# WKUP_CTRL_MMR0_CFG0 register map
Vendor: Texas Instruments
Registers are 32-bit, read-write, reset 0x0 unless marked. A register's access mark holds for its fields unless they carry their own. Offsets are as the file gives them; [hi:lo] are bit positions; {n}, {i} and the like mark numbered series.

## WKUP_CTRL_MMR0_CFG0 (part 11 of 11)
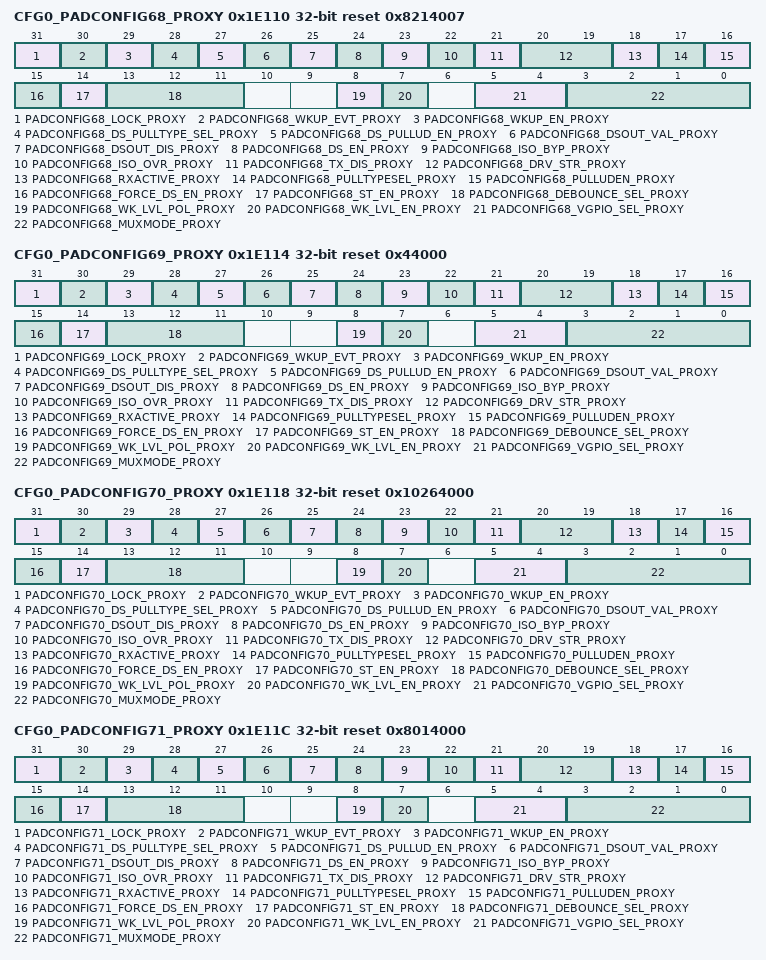
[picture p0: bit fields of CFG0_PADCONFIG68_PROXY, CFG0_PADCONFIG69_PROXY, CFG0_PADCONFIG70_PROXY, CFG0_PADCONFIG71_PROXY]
0x1E110 CFG0_PADCONFIG68_PROXY access per field reset 0x8214007
  [31] PADCONFIG68_LOCK_PROXY rw — Lock 0 - Padconfig register is unlocked 1 - Padconfig register is locked from further writes
  [30] PADCONFIG68_WKUP_EVT_PROXY ro — Wakeup event status 0 - No wake event on pin 1 - Wake event occurred on pin
  [29] PADCONFIG68_WKUP_EN_PROXY rw — Wakeup enable 0 - Wakeup operation disabled 1 - Wakeup operation enabled
  [28] PADCONFIG68_DS_PULLTYPE_SEL_PROXY rw — Deep Sleep pull-up/down selection 0 - Offmode pulldown selected 1 - Offmode pullup selected
  [27] PADCONFIG68_DS_PULLUD_EN_PROXY rw — Deep Sleep pull-up/down enable (active low) 0 - Pullup / pulldown is enabled 1 - Pullup / pulldown is disabled
  [26] PADCONFIG68_DSOUT_VAL_PROXY rw — Deep Sleep output value 0 - Output value is 0 1 - Output value is 1
  [25] PADCONFIG68_DSOUT_DIS_PROXY rw — Deep Sleep output enable 0 - Output enabled 1 - Output disabled
  [24] PADCONFIG68_DS_EN_PROXY rw — Deep Sleep override control 0 - IO keeps its previous state when Deep Sleep is active 1 - IO state is forced to OFF mode value when Deep Sleep is active
  [23] PADCONFIG68_ISO_BYP_PROXY rw — Isolation Bypass 0 - IO isolation is preserved 1 - IO isolation is bypassed
  [22] PADCONFIG68_ISO_OVR_PROXY rw — Isolation Override 0 - IO isolation is preserved 1 - IO isolation is overridden
  [21] PADCONFIG68_TX_DIS_PROXY rw — Driver Disable 0 - Driver is enabled 1 - Driver is disabled
  [20:19] PADCONFIG68_DRV_STR_PROXY rw — Drive Strength Control . Selects the drive strength value for LVCMOS pins. (Does not apply to other pin types)
  [18] PADCONFIG68_RXACTIVE_PROXY rw — Input enable for the Pad 0 - Receiver disabled 1 - Receiver enabled
  [17] PADCONFIG68_PULLTYPESEL_PROXY rw — Pad Pullup / Pulldown type selection 0 - Pulldown selected 1 - Pullup selected
  [16] PADCONFIG68_PULLUDEN_PROXY rw — Pad Pullup / Pulldown enable. This is an active low signal. 0 - Pullup / Pulldown enabled 1 - Pullup / Pulldown disabled
  [15] PADCONFIG68_FORCE_DS_EN_PROXY rw — Enable pad Deep Sleep controls by overriding SMS gating 0 - Deep Sleep pad controls are gated by the SMS 1 - Activate Deep Sleep pad controls (override SMS gating logic)
  [14] PADCONFIG68_ST_EN_PROXY rw — Receiver Schmitt Trigger enable 0 - Schmitt trigger input disabled 1 - Schmitt trigger input enabled
  [13:11] PADCONFIG68_DEBOUNCE_SEL_PROXY rw — Selects the debounce period for the pad.
  [8] PADCONFIG68_WK_LVL_POL_PROXY rw — Level Sensitive Wakeup Polarity This bit is not relevant unless wk_lvl_en is set to 1'b1. 0 - Low. A low (0) value on the pin causes a wakeup 1 - High. A high (1) value on the pin causes a wakeup
  [7] PADCONFIG68_WK_LVL_EN_PROXY rw — Level Sensitive Wakeup Enable 0 - Disabled. Wakeup is triggered by change of the pin input value 1 - Enabled. Wakeup is triggered when the pin matches the value specified by wk_lvl_pol. The chosen polarity must be maintained. (e.g. until wakeup completion is confirmed)
  [5:4] PADCONFIG68_VGPIO_SEL_PROXY rw — Virtual WKUP_GPIO instance select. These bits select which instance of GPIO is used for this I/O pad. This allows protection between two different Processor virtual worlds. These bits have no effect if GPIO mode (muxmode=7) is not selected for the PAD. Field values (others are reserved): 2'b00 - Implement GPIO in GPIO_WKUP_0 instance 2'b01 - Implement GPIO in GPIO_WKUP_1 instance
  [3:0] PADCONFIG68_MUXMODE_PROXY rw — Pad functional signal mux selection Field values (others are reserved): 0000b - Mux Mode 0 0001b - Mux Mode 1 0010b - Mux Mode 2 0011b - Mux Mode 3 0100b - Mux Mode 4 0101b - Mux Mode 5 0110b - Mux Mode 6 0111b - Mux Mode 7 1111b - Mux Mode 15
0x1E114 CFG0_PADCONFIG69_PROXY access per field reset 0x44000
  [31] PADCONFIG69_LOCK_PROXY rw — Lock 0 - Padconfig register is unlocked 1 - Padconfig register is locked from further writes
  [30] PADCONFIG69_WKUP_EVT_PROXY ro — Wakeup event status 0 - No wake event on pin 1 - Wake event occurred on pin
  [29] PADCONFIG69_WKUP_EN_PROXY rw — Wakeup enable 0 - Wakeup operation disabled 1 - Wakeup operation enabled
  [28] PADCONFIG69_DS_PULLTYPE_SEL_PROXY rw — Deep Sleep pull-up/down selection 0 - Offmode pulldown selected 1 - Offmode pullup selected
  [27] PADCONFIG69_DS_PULLUD_EN_PROXY rw — Deep Sleep pull-up/down enable (active low) 0 - Pullup / pulldown is enabled 1 - Pullup / pulldown is disabled
  [26] PADCONFIG69_DSOUT_VAL_PROXY rw — Deep Sleep output value 0 - Output value is 0 1 - Output value is 1
  [25] PADCONFIG69_DSOUT_DIS_PROXY rw — Deep Sleep output enable 0 - Output enabled 1 - Output disabled
  [24] PADCONFIG69_DS_EN_PROXY rw — Deep Sleep override control 0 - IO keeps its previous state when Deep Sleep is active 1 - IO state is forced to OFF mode value when Deep Sleep is active
  [23] PADCONFIG69_ISO_BYP_PROXY rw — Isolation Bypass 0 - IO isolation is preserved 1 - IO isolation is bypassed
  [22] PADCONFIG69_ISO_OVR_PROXY rw — Isolation Override 0 - IO isolation is preserved 1 - IO isolation is overridden
  [21] PADCONFIG69_TX_DIS_PROXY rw — Driver Disable 0 - Driver is enabled 1 - Driver is disabled
  [20:19] PADCONFIG69_DRV_STR_PROXY rw — Drive Strength Control . Selects the drive strength value for LVCMOS pins. (Does not apply to other pin types)
  [18] PADCONFIG69_RXACTIVE_PROXY rw — Input enable for the Pad 0 - Receiver disabled 1 - Receiver enabled
  [17] PADCONFIG69_PULLTYPESEL_PROXY rw — Pad Pullup / Pulldown type selection 0 - Pulldown selected 1 - Pullup selected
  [16] PADCONFIG69_PULLUDEN_PROXY rw — Pad Pullup / Pulldown enable. This is an active low signal. 0 - Pullup / Pulldown enabled 1 - Pullup / Pulldown disabled
  [15] PADCONFIG69_FORCE_DS_EN_PROXY rw — Enable pad Deep Sleep controls by overriding SMS gating 0 - Deep Sleep pad controls are gated by the SMS 1 - Activate Deep Sleep pad controls (override SMS gating logic)
  [14] PADCONFIG69_ST_EN_PROXY rw — Receiver Schmitt Trigger enable 0 - Schmitt trigger input disabled 1 - Schmitt trigger input enabled
  [13:11] PADCONFIG69_DEBOUNCE_SEL_PROXY rw — Selects the debounce period for the pad.
  [8] PADCONFIG69_WK_LVL_POL_PROXY rw — Level Sensitive Wakeup Polarity This bit is not relevant unless wk_lvl_en is set to 1'b1. 0 - Low. A low (0) value on the pin causes a wakeup 1 - High. A high (1) value on the pin causes a wakeup
  [7] PADCONFIG69_WK_LVL_EN_PROXY rw — Level Sensitive Wakeup Enable 0 - Disabled. Wakeup is triggered by change of the pin input value 1 - Enabled. Wakeup is triggered when the pin matches the value specified by wk_lvl_pol. The chosen polarity must be maintained. (e.g. until wakeup completion is confirmed)
  [5:4] PADCONFIG69_VGPIO_SEL_PROXY rw — Virtual WKUP_GPIO instance select. These bits select which instance of GPIO is used for this I/O pad. This allows protection between two different Processor virtual worlds. These bits have no effect if GPIO mode (muxmode=7) is not selected for the PAD. Field values (others are reserved): 2'b00 - Implement GPIO in GPIO_WKUP_0 instance 2'b01 - Implement GPIO in GPIO_WKUP_1 instance
  [3:0] PADCONFIG69_MUXMODE_PROXY rw — Pad functional signal mux selection Field values (others are reserved): 0000b - Mux Mode 0 0001b - Mux Mode 1 0010b - Mux Mode 2 0011b - Mux Mode 3 0100b - Mux Mode 4 0101b - Mux Mode 5 0110b - Mux Mode 6 0111b - Mux Mode 7 1111b - Mux Mode 15
0x1E118 CFG0_PADCONFIG70_PROXY access per field reset 0x10264000
  [31] PADCONFIG70_LOCK_PROXY rw — Lock 0 - Padconfig register is unlocked 1 - Padconfig register is locked from further writes
  [30] PADCONFIG70_WKUP_EVT_PROXY ro — Wakeup event status 0 - No wake event on pin 1 - Wake event occurred on pin
  [29] PADCONFIG70_WKUP_EN_PROXY rw — Wakeup enable 0 - Wakeup operation disabled 1 - Wakeup operation enabled
  [28] PADCONFIG70_DS_PULLTYPE_SEL_PROXY rw — Deep Sleep pull-up/down selection 0 - Offmode pulldown selected 1 - Offmode pullup selected
  [27] PADCONFIG70_DS_PULLUD_EN_PROXY rw — Deep Sleep pull-up/down enable (active low) 0 - Pullup / pulldown is enabled 1 - Pullup / pulldown is disabled
  [26] PADCONFIG70_DSOUT_VAL_PROXY rw — Deep Sleep output value 0 - Output value is 0 1 - Output value is 1
  [25] PADCONFIG70_DSOUT_DIS_PROXY rw — Deep Sleep output enable 0 - Output enabled 1 - Output disabled
  [24] PADCONFIG70_DS_EN_PROXY rw — Deep Sleep override control 0 - IO keeps its previous state when Deep Sleep is active 1 - IO state is forced to OFF mode value when Deep Sleep is active
  [23] PADCONFIG70_ISO_BYP_PROXY rw — Isolation Bypass 0 - IO isolation is preserved 1 - IO isolation is bypassed
  [22] PADCONFIG70_ISO_OVR_PROXY rw — Isolation Override 0 - IO isolation is preserved 1 - IO isolation is overridden
  [21] PADCONFIG70_TX_DIS_PROXY rw — Driver Disable 0 - Driver is enabled 1 - Driver is disabled
  [20:19] PADCONFIG70_DRV_STR_PROXY rw — Drive Strength Control . Selects the drive strength value for LVCMOS pins. (Does not apply to other pin types)
  [18] PADCONFIG70_RXACTIVE_PROXY rw — Input enable for the Pad 0 - Receiver disabled 1 - Receiver enabled
  [17] PADCONFIG70_PULLTYPESEL_PROXY rw — Pad Pullup / Pulldown type selection 0 - Pulldown selected 1 - Pullup selected
  [16] PADCONFIG70_PULLUDEN_PROXY rw — Pad Pullup / Pulldown enable. This is an active low signal. 0 - Pullup / Pulldown enabled 1 - Pullup / Pulldown disabled
  [15] PADCONFIG70_FORCE_DS_EN_PROXY rw — Enable pad Deep Sleep controls by overriding SMS gating 0 - Deep Sleep pad controls are gated by the SMS 1 - Activate Deep Sleep pad controls (override SMS gating logic)
  [14] PADCONFIG70_ST_EN_PROXY rw — Receiver Schmitt Trigger enable 0 - Schmitt trigger input disabled 1 - Schmitt trigger input enabled
  [13:11] PADCONFIG70_DEBOUNCE_SEL_PROXY rw — Selects the debounce period for the pad.
  [8] PADCONFIG70_WK_LVL_POL_PROXY rw — Level Sensitive Wakeup Polarity This bit is not relevant unless wk_lvl_en is set to 1'b1. 0 - Low. A low (0) value on the pin causes a wakeup 1 - High. A high (1) value on the pin causes a wakeup
  [7] PADCONFIG70_WK_LVL_EN_PROXY rw — Level Sensitive Wakeup Enable 0 - Disabled. Wakeup is triggered by change of the pin input value 1 - Enabled. Wakeup is triggered when the pin matches the value specified by wk_lvl_pol. The chosen polarity must be maintained. (e.g. until wakeup completion is confirmed)
  [5:4] PADCONFIG70_VGPIO_SEL_PROXY rw — Virtual WKUP_GPIO instance select. These bits select which instance of GPIO is used for this I/O pad. This allows protection between two different Processor virtual worlds. These bits have no effect if GPIO mode (muxmode=7) is not selected for the PAD. Field values (others are reserved): 2'b00 - Implement GPIO in GPIO_WKUP_0 instance 2'b01 - Implement GPIO in GPIO_WKUP_1 instance
  [3:0] PADCONFIG70_MUXMODE_PROXY rw — Pad functional signal mux selection Field values (others are reserved): 0000b - Mux Mode 0 0001b - Mux Mode 1 0010b - Mux Mode 2 0011b - Mux Mode 3 0100b - Mux Mode 4 0101b - Mux Mode 5 0110b - Mux Mode 6 0111b - Mux Mode 7 1111b - Mux Mode 15
0x1E11C CFG0_PADCONFIG71_PROXY access per field reset 0x8014000
  [31] PADCONFIG71_LOCK_PROXY rw — Lock 0 - Padconfig register is unlocked 1 - Padconfig register is locked from further writes
  [30] PADCONFIG71_WKUP_EVT_PROXY ro — Wakeup event status 0 - No wake event on pin 1 - Wake event occurred on pin
  [29] PADCONFIG71_WKUP_EN_PROXY rw — Wakeup enable 0 - Wakeup operation disabled 1 - Wakeup operation enabled
  [28] PADCONFIG71_DS_PULLTYPE_SEL_PROXY rw — Deep Sleep pull-up/down selection 0 - Offmode pulldown selected 1 - Offmode pullup selected
  [27] PADCONFIG71_DS_PULLUD_EN_PROXY rw — Deep Sleep pull-up/down enable (active low) 0 - Pullup / pulldown is enabled 1 - Pullup / pulldown is disabled
  [26] PADCONFIG71_DSOUT_VAL_PROXY rw — Deep Sleep output value 0 - Output value is 0 1 - Output value is 1
  [25] PADCONFIG71_DSOUT_DIS_PROXY rw — Deep Sleep output enable 0 - Output enabled 1 - Output disabled
  [24] PADCONFIG71_DS_EN_PROXY rw — Deep Sleep override control 0 - IO keeps its previous state when Deep Sleep is active 1 - IO state is forced to OFF mode value when Deep Sleep is active
  [23] PADCONFIG71_ISO_BYP_PROXY rw — Isolation Bypass 0 - IO isolation is preserved 1 - IO isolation is bypassed
  [22] PADCONFIG71_ISO_OVR_PROXY rw — Isolation Override 0 - IO isolation is preserved 1 - IO isolation is overridden
  [21] PADCONFIG71_TX_DIS_PROXY rw — Driver Disable 0 - Driver is enabled 1 - Driver is disabled
  [20:19] PADCONFIG71_DRV_STR_PROXY rw — Drive Strength Control . Selects the drive strength value for LVCMOS pins. (Does not apply to other pin types)
  [18] PADCONFIG71_RXACTIVE_PROXY rw — Input enable for the Pad 0 - Receiver disabled 1 - Receiver enabled
  [17] PADCONFIG71_PULLTYPESEL_PROXY rw — Pad Pullup / Pulldown type selection 0 - Pulldown selected 1 - Pullup selected
  [16] PADCONFIG71_PULLUDEN_PROXY rw — Pad Pullup / Pulldown enable. This is an active low signal. 0 - Pullup / Pulldown enabled 1 - Pullup / Pulldown disabled
  [15] PADCONFIG71_FORCE_DS_EN_PROXY rw — Enable pad Deep Sleep controls by overriding SMS gating 0 - Deep Sleep pad controls are gated by the SMS 1 - Activate Deep Sleep pad controls (override SMS gating logic)
  [14] PADCONFIG71_ST_EN_PROXY rw — Receiver Schmitt Trigger enable 0 - Schmitt trigger input disabled 1 - Schmitt trigger input enabled
  [13:11] PADCONFIG71_DEBOUNCE_SEL_PROXY rw — Selects the debounce period for the pad.
  [8] PADCONFIG71_WK_LVL_POL_PROXY rw — Level Sensitive Wakeup Polarity This bit is not relevant unless wk_lvl_en is set to 1'b1. 0 - Low. A low (0) value on the pin causes a wakeup 1 - High. A high (1) value on the pin causes a wakeup
  [7] PADCONFIG71_WK_LVL_EN_PROXY rw — Level Sensitive Wakeup Enable 0 - Disabled. Wakeup is triggered by change of the pin input value 1 - Enabled. Wakeup is triggered when the pin matches the value specified by wk_lvl_pol. The chosen polarity must be maintained. (e.g. until wakeup completion is confirmed)
  [5:4] PADCONFIG71_VGPIO_SEL_PROXY rw — Virtual WKUP_GPIO instance select. These bits select which instance of GPIO is used for this I/O pad. This allows protection between two different Processor virtual worlds. These bits have no effect if GPIO mode (muxmode=7) is not selected for the PAD. Field values (others are reserved): 2'b00 - Implement GPIO in GPIO_WKUP_0 instance 2'b01 - Implement GPIO in GPIO_WKUP_1 instance
  [3:0] PADCONFIG71_MUXMODE_PROXY rw — Pad functional signal mux selection Field values (others are reserved): 0000b - Mux Mode 0 0001b - Mux Mode 1 0010b - Mux Mode 2 0011b - Mux Mode 3 0100b - Mux Mode 4 0101b - Mux Mode 5 0110b - Mux Mode 6 0111b - Mux Mode 7 1111b - Mux Mode 15
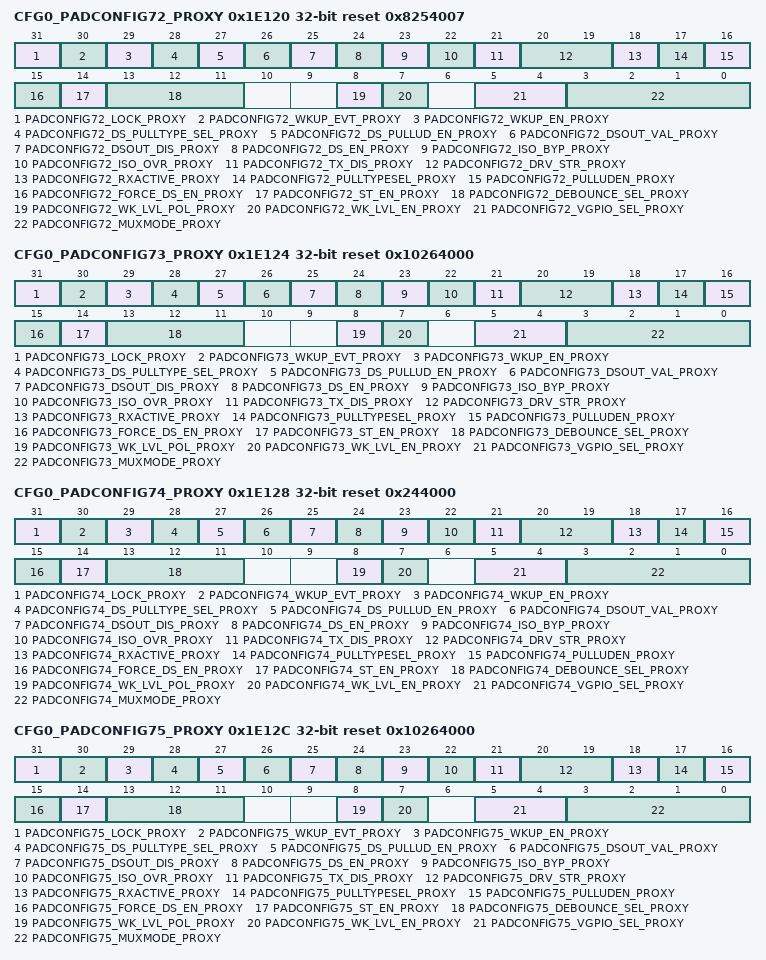
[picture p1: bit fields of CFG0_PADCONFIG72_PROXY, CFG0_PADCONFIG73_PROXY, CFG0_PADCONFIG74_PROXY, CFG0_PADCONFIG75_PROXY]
0x1E120 CFG0_PADCONFIG72_PROXY access per field reset 0x8254007
  [31] PADCONFIG72_LOCK_PROXY rw — Lock 0 - Padconfig register is unlocked 1 - Padconfig register is locked from further writes
  [30] PADCONFIG72_WKUP_EVT_PROXY ro — Wakeup event status 0 - No wake event on pin 1 - Wake event occurred on pin
  [29] PADCONFIG72_WKUP_EN_PROXY rw — Wakeup enable 0 - Wakeup operation disabled 1 - Wakeup operation enabled
  [28] PADCONFIG72_DS_PULLTYPE_SEL_PROXY rw — Deep Sleep pull-up/down selection 0 - Offmode pulldown selected 1 - Offmode pullup selected
  [27] PADCONFIG72_DS_PULLUD_EN_PROXY rw — Deep Sleep pull-up/down enable (active low) 0 - Pullup / pulldown is enabled 1 - Pullup / pulldown is disabled
  [26] PADCONFIG72_DSOUT_VAL_PROXY rw — Deep Sleep output value 0 - Output value is 0 1 - Output value is 1
  [25] PADCONFIG72_DSOUT_DIS_PROXY rw — Deep Sleep output enable 0 - Output enabled 1 - Output disabled
  [24] PADCONFIG72_DS_EN_PROXY rw — Deep Sleep override control 0 - IO keeps its previous state when Deep Sleep is active 1 - IO state is forced to OFF mode value when Deep Sleep is active
  [23] PADCONFIG72_ISO_BYP_PROXY rw — Isolation Bypass 0 - IO isolation is preserved 1 - IO isolation is bypassed
  [22] PADCONFIG72_ISO_OVR_PROXY rw — Isolation Override 0 - IO isolation is preserved 1 - IO isolation is overridden
  [21] PADCONFIG72_TX_DIS_PROXY rw — Driver Disable 0 - Driver is enabled 1 - Driver is disabled
  [20:19] PADCONFIG72_DRV_STR_PROXY rw — Drive Strength Control . Selects the drive strength value for LVCMOS pins. (Does not apply to other pin types)
  [18] PADCONFIG72_RXACTIVE_PROXY rw — Input enable for the Pad 0 - Receiver disabled 1 - Receiver enabled
  [17] PADCONFIG72_PULLTYPESEL_PROXY rw — Pad Pullup / Pulldown type selection 0 - Pulldown selected 1 - Pullup selected
  [16] PADCONFIG72_PULLUDEN_PROXY rw — Pad Pullup / Pulldown enable. This is an active low signal. 0 - Pullup / Pulldown enabled 1 - Pullup / Pulldown disabled
  [15] PADCONFIG72_FORCE_DS_EN_PROXY rw — Enable pad Deep Sleep controls by overriding SMS gating 0 - Deep Sleep pad controls are gated by the SMS 1 - Activate Deep Sleep pad controls (override SMS gating logic)
  [14] PADCONFIG72_ST_EN_PROXY rw — Receiver Schmitt Trigger enable 0 - Schmitt trigger input disabled 1 - Schmitt trigger input enabled
  [13:11] PADCONFIG72_DEBOUNCE_SEL_PROXY rw — Selects the debounce period for the pad.
  [8] PADCONFIG72_WK_LVL_POL_PROXY rw — Level Sensitive Wakeup Polarity This bit is not relevant unless wk_lvl_en is set to 1'b1. 0 - Low. A low (0) value on the pin causes a wakeup 1 - High. A high (1) value on the pin causes a wakeup
  [7] PADCONFIG72_WK_LVL_EN_PROXY rw — Level Sensitive Wakeup Enable 0 - Disabled. Wakeup is triggered by change of the pin input value 1 - Enabled. Wakeup is triggered when the pin matches the value specified by wk_lvl_pol. The chosen polarity must be maintained. (e.g. until wakeup completion is confirmed)
  [5:4] PADCONFIG72_VGPIO_SEL_PROXY rw — Virtual WKUP_GPIO instance select. These bits select which instance of GPIO is used for this I/O pad. This allows protection between two different Processor virtual worlds. These bits have no effect if GPIO mode (muxmode=7) is not selected for the PAD. Field values (others are reserved): 2'b00 - Implement GPIO in GPIO_WKUP_0 instance 2'b01 - Implement GPIO in GPIO_WKUP_1 instance
  [3:0] PADCONFIG72_MUXMODE_PROXY rw — Pad functional signal mux selection Field values (others are reserved): 0000b - Mux Mode 0 0001b - Mux Mode 1 0010b - Mux Mode 2 0011b - Mux Mode 3 0100b - Mux Mode 4 0101b - Mux Mode 5 0110b - Mux Mode 6 0111b - Mux Mode 7 1111b - Mux Mode 15
0x1E124 CFG0_PADCONFIG73_PROXY access per field reset 0x10264000
  [31] PADCONFIG73_LOCK_PROXY rw — Lock 0 - Padconfig register is unlocked 1 - Padconfig register is locked from further writes
  [30] PADCONFIG73_WKUP_EVT_PROXY ro — Wakeup event status 0 - No wake event on pin 1 - Wake event occurred on pin
  [29] PADCONFIG73_WKUP_EN_PROXY rw — Wakeup enable 0 - Wakeup operation disabled 1 - Wakeup operation enabled
  [28] PADCONFIG73_DS_PULLTYPE_SEL_PROXY rw — Deep Sleep pull-up/down selection 0 - Offmode pulldown selected 1 - Offmode pullup selected
  [27] PADCONFIG73_DS_PULLUD_EN_PROXY rw — Deep Sleep pull-up/down enable (active low) 0 - Pullup / pulldown is enabled 1 - Pullup / pulldown is disabled
  [26] PADCONFIG73_DSOUT_VAL_PROXY rw — Deep Sleep output value 0 - Output value is 0 1 - Output value is 1
  [25] PADCONFIG73_DSOUT_DIS_PROXY rw — Deep Sleep output enable 0 - Output enabled 1 - Output disabled
  [24] PADCONFIG73_DS_EN_PROXY rw — Deep Sleep override control 0 - IO keeps its previous state when Deep Sleep is active 1 - IO state is forced to OFF mode value when Deep Sleep is active
  [23] PADCONFIG73_ISO_BYP_PROXY rw — Isolation Bypass 0 - IO isolation is preserved 1 - IO isolation is bypassed
  [22] PADCONFIG73_ISO_OVR_PROXY rw — Isolation Override 0 - IO isolation is preserved 1 - IO isolation is overridden
  [21] PADCONFIG73_TX_DIS_PROXY rw — Driver Disable 0 - Driver is enabled 1 - Driver is disabled
  [20:19] PADCONFIG73_DRV_STR_PROXY rw — Drive Strength Control . Selects the drive strength value for LVCMOS pins. (Does not apply to other pin types)
  [18] PADCONFIG73_RXACTIVE_PROXY rw — Input enable for the Pad 0 - Receiver disabled 1 - Receiver enabled
  [17] PADCONFIG73_PULLTYPESEL_PROXY rw — Pad Pullup / Pulldown type selection 0 - Pulldown selected 1 - Pullup selected
  [16] PADCONFIG73_PULLUDEN_PROXY rw — Pad Pullup / Pulldown enable. This is an active low signal. 0 - Pullup / Pulldown enabled 1 - Pullup / Pulldown disabled
  [15] PADCONFIG73_FORCE_DS_EN_PROXY rw — Enable pad Deep Sleep controls by overriding SMS gating 0 - Deep Sleep pad controls are gated by the SMS 1 - Activate Deep Sleep pad controls (override SMS gating logic)
  [14] PADCONFIG73_ST_EN_PROXY rw — Receiver Schmitt Trigger enable 0 - Schmitt trigger input disabled 1 - Schmitt trigger input enabled
  [13:11] PADCONFIG73_DEBOUNCE_SEL_PROXY rw — Selects the debounce period for the pad.
  [8] PADCONFIG73_WK_LVL_POL_PROXY rw — Level Sensitive Wakeup Polarity This bit is not relevant unless wk_lvl_en is set to 1'b1. 0 - Low. A low (0) value on the pin causes a wakeup 1 - High. A high (1) value on the pin causes a wakeup
  [7] PADCONFIG73_WK_LVL_EN_PROXY rw — Level Sensitive Wakeup Enable 0 - Disabled. Wakeup is triggered by change of the pin input value 1 - Enabled. Wakeup is triggered when the pin matches the value specified by wk_lvl_pol. The chosen polarity must be maintained. (e.g. until wakeup completion is confirmed)
  [5:4] PADCONFIG73_VGPIO_SEL_PROXY rw — Virtual WKUP_GPIO instance select. These bits select which instance of GPIO is used for this I/O pad. This allows protection between two different Processor virtual worlds. These bits have no effect if GPIO mode (muxmode=7) is not selected for the PAD. Field values (others are reserved): 2'b00 - Implement GPIO in GPIO_WKUP_0 instance 2'b01 - Implement GPIO in GPIO_WKUP_1 instance
  [3:0] PADCONFIG73_MUXMODE_PROXY rw — Pad functional signal mux selection Field values (others are reserved): 0000b - Mux Mode 0 0001b - Mux Mode 1 0010b - Mux Mode 2 0011b - Mux Mode 3 0100b - Mux Mode 4 0101b - Mux Mode 5 0110b - Mux Mode 6 0111b - Mux Mode 7 1111b - Mux Mode 15
0x1E128 CFG0_PADCONFIG74_PROXY access per field reset 0x244000
  [31] PADCONFIG74_LOCK_PROXY rw — Lock 0 - Padconfig register is unlocked 1 - Padconfig register is locked from further writes
  [30] PADCONFIG74_WKUP_EVT_PROXY ro — Wakeup event status 0 - No wake event on pin 1 - Wake event occurred on pin
  [29] PADCONFIG74_WKUP_EN_PROXY rw — Wakeup enable 0 - Wakeup operation disabled 1 - Wakeup operation enabled
  [28] PADCONFIG74_DS_PULLTYPE_SEL_PROXY rw — Deep Sleep pull-up/down selection 0 - Offmode pulldown selected 1 - Offmode pullup selected
  [27] PADCONFIG74_DS_PULLUD_EN_PROXY rw — Deep Sleep pull-up/down enable (active low) 0 - Pullup / pulldown is enabled 1 - Pullup / pulldown is disabled
  [26] PADCONFIG74_DSOUT_VAL_PROXY rw — Deep Sleep output value 0 - Output value is 0 1 - Output value is 1
  [25] PADCONFIG74_DSOUT_DIS_PROXY rw — Deep Sleep output enable 0 - Output enabled 1 - Output disabled
  [24] PADCONFIG74_DS_EN_PROXY rw — Deep Sleep override control 0 - IO keeps its previous state when Deep Sleep is active 1 - IO state is forced to OFF mode value when Deep Sleep is active
  [23] PADCONFIG74_ISO_BYP_PROXY rw — Isolation Bypass 0 - IO isolation is preserved 1 - IO isolation is bypassed
  [22] PADCONFIG74_ISO_OVR_PROXY rw — Isolation Override 0 - IO isolation is preserved 1 - IO isolation is overridden
  [21] PADCONFIG74_TX_DIS_PROXY rw — Driver Disable 0 - Driver is enabled 1 - Driver is disabled
  [20:19] PADCONFIG74_DRV_STR_PROXY rw — Drive Strength Control . Selects the drive strength value for LVCMOS pins. (Does not apply to other pin types)
  [18] PADCONFIG74_RXACTIVE_PROXY rw — Input enable for the Pad 0 - Receiver disabled 1 - Receiver enabled
  [17] PADCONFIG74_PULLTYPESEL_PROXY rw — Pad Pullup / Pulldown type selection 0 - Pulldown selected 1 - Pullup selected
  [16] PADCONFIG74_PULLUDEN_PROXY rw — Pad Pullup / Pulldown enable. This is an active low signal. 0 - Pullup / Pulldown enabled 1 - Pullup / Pulldown disabled
  [15] PADCONFIG74_FORCE_DS_EN_PROXY rw — Enable pad Deep Sleep controls by overriding SMS gating 0 - Deep Sleep pad controls are gated by the SMS 1 - Activate Deep Sleep pad controls (override SMS gating logic)
  [14] PADCONFIG74_ST_EN_PROXY rw — Receiver Schmitt Trigger enable 0 - Schmitt trigger input disabled 1 - Schmitt trigger input enabled
  [13:11] PADCONFIG74_DEBOUNCE_SEL_PROXY rw — Selects the debounce period for the pad.
  [8] PADCONFIG74_WK_LVL_POL_PROXY rw — Level Sensitive Wakeup Polarity This bit is not relevant unless wk_lvl_en is set to 1'b1. 0 - Low. A low (0) value on the pin causes a wakeup 1 - High. A high (1) value on the pin causes a wakeup
  [7] PADCONFIG74_WK_LVL_EN_PROXY rw — Level Sensitive Wakeup Enable 0 - Disabled. Wakeup is triggered by change of the pin input value 1 - Enabled. Wakeup is triggered when the pin matches the value specified by wk_lvl_pol. The chosen polarity must be maintained. (e.g. until wakeup completion is confirmed)
  [5:4] PADCONFIG74_VGPIO_SEL_PROXY rw — Virtual WKUP_GPIO instance select. These bits select which instance of GPIO is used for this I/O pad. This allows protection between two different Processor virtual worlds. These bits have no effect if GPIO mode (muxmode=7) is not selected for the PAD. Field values (others are reserved): 2'b00 - Implement GPIO in GPIO_WKUP_0 instance 2'b01 - Implement GPIO in GPIO_WKUP_1 instance
  [3:0] PADCONFIG74_MUXMODE_PROXY rw — Pad functional signal mux selection Field values (others are reserved): 0000b - Mux Mode 0 0001b - Mux Mode 1 0010b - Mux Mode 2 0011b - Mux Mode 3 0100b - Mux Mode 4 0101b - Mux Mode 5 0110b - Mux Mode 6 0111b - Mux Mode 7 1111b - Mux Mode 15
0x1E12C CFG0_PADCONFIG75_PROXY access per field reset 0x10264000
  [31] PADCONFIG75_LOCK_PROXY rw — Lock 0 - Padconfig register is unlocked 1 - Padconfig register is locked from further writes
  [30] PADCONFIG75_WKUP_EVT_PROXY ro — Wakeup event status 0 - No wake event on pin 1 - Wake event occurred on pin
  [29] PADCONFIG75_WKUP_EN_PROXY rw — Wakeup enable 0 - Wakeup operation disabled 1 - Wakeup operation enabled
  [28] PADCONFIG75_DS_PULLTYPE_SEL_PROXY rw — Deep Sleep pull-up/down selection 0 - Offmode pulldown selected 1 - Offmode pullup selected
  [27] PADCONFIG75_DS_PULLUD_EN_PROXY rw — Deep Sleep pull-up/down enable (active low) 0 - Pullup / pulldown is enabled 1 - Pullup / pulldown is disabled
  [26] PADCONFIG75_DSOUT_VAL_PROXY rw — Deep Sleep output value 0 - Output value is 0 1 - Output value is 1
  [25] PADCONFIG75_DSOUT_DIS_PROXY rw — Deep Sleep output enable 0 - Output enabled 1 - Output disabled
  [24] PADCONFIG75_DS_EN_PROXY rw — Deep Sleep override control 0 - IO keeps its previous state when Deep Sleep is active 1 - IO state is forced to OFF mode value when Deep Sleep is active
  [23] PADCONFIG75_ISO_BYP_PROXY rw — Isolation Bypass 0 - IO isolation is preserved 1 - IO isolation is bypassed
  [22] PADCONFIG75_ISO_OVR_PROXY rw — Isolation Override 0 - IO isolation is preserved 1 - IO isolation is overridden
  [21] PADCONFIG75_TX_DIS_PROXY rw — Driver Disable 0 - Driver is enabled 1 - Driver is disabled
  [20:19] PADCONFIG75_DRV_STR_PROXY rw — Drive Strength Control . Selects the drive strength value for LVCMOS pins. (Does not apply to other pin types)
  [18] PADCONFIG75_RXACTIVE_PROXY rw — Input enable for the Pad 0 - Receiver disabled 1 - Receiver enabled
  [17] PADCONFIG75_PULLTYPESEL_PROXY rw — Pad Pullup / Pulldown type selection 0 - Pulldown selected 1 - Pullup selected
  [16] PADCONFIG75_PULLUDEN_PROXY rw — Pad Pullup / Pulldown enable. This is an active low signal. 0 - Pullup / Pulldown enabled 1 - Pullup / Pulldown disabled
  [15] PADCONFIG75_FORCE_DS_EN_PROXY rw — Enable pad Deep Sleep controls by overriding SMS gating 0 - Deep Sleep pad controls are gated by the SMS 1 - Activate Deep Sleep pad controls (override SMS gating logic)
  [14] PADCONFIG75_ST_EN_PROXY rw — Receiver Schmitt Trigger enable 0 - Schmitt trigger input disabled 1 - Schmitt trigger input enabled
  [13:11] PADCONFIG75_DEBOUNCE_SEL_PROXY rw — Selects the debounce period for the pad.
  [8] PADCONFIG75_WK_LVL_POL_PROXY rw — Level Sensitive Wakeup Polarity This bit is not relevant unless wk_lvl_en is set to 1'b1. 0 - Low. A low (0) value on the pin causes a wakeup 1 - High. A high (1) value on the pin causes a wakeup
  [7] PADCONFIG75_WK_LVL_EN_PROXY rw — Level Sensitive Wakeup Enable 0 - Disabled. Wakeup is triggered by change of the pin input value 1 - Enabled. Wakeup is triggered when the pin matches the value specified by wk_lvl_pol. The chosen polarity must be maintained. (e.g. until wakeup completion is confirmed)
  [5:4] PADCONFIG75_VGPIO_SEL_PROXY rw — Virtual WKUP_GPIO instance select. These bits select which instance of GPIO is used for this I/O pad. This allows protection between two different Processor virtual worlds. These bits have no effect if GPIO mode (muxmode=7) is not selected for the PAD. Field values (others are reserved): 2'b00 - Implement GPIO in GPIO_WKUP_0 instance 2'b01 - Implement GPIO in GPIO_WKUP_1 instance
  [3:0] PADCONFIG75_MUXMODE_PROXY rw — Pad functional signal mux selection Field values (others are reserved): 0000b - Mux Mode 0 0001b - Mux Mode 1 0010b - Mux Mode 2 0011b - Mux Mode 3 0100b - Mux Mode 4 0101b - Mux Mode 5 0110b - Mux Mode 6 0111b - Mux Mode 7 1111b - Mux Mode 15
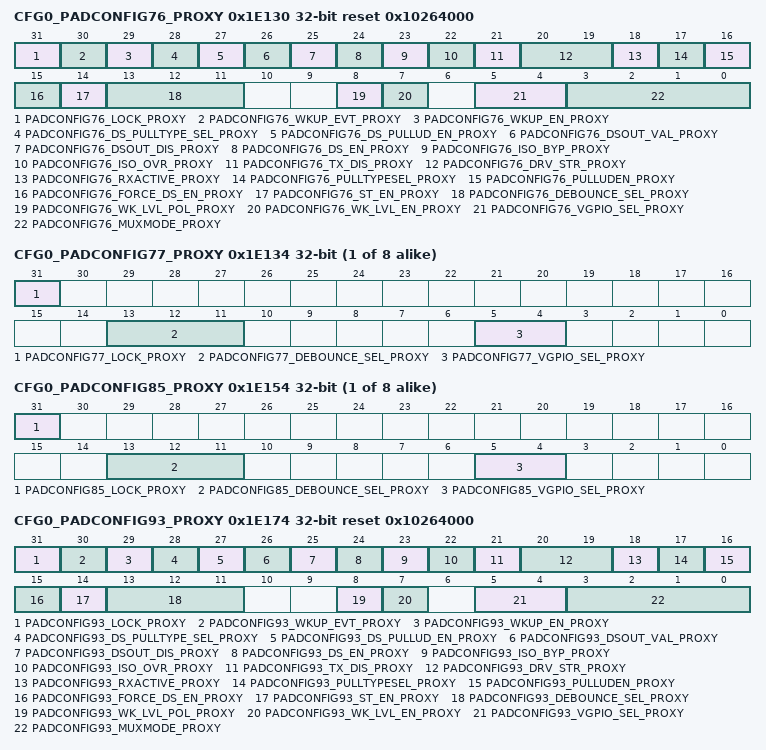
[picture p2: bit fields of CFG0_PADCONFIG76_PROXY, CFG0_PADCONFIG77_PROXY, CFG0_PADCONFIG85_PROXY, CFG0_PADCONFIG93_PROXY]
0x1E130 CFG0_PADCONFIG76_PROXY access per field reset 0x10264000
  [31] PADCONFIG76_LOCK_PROXY rw — Lock 0 - Padconfig register is unlocked 1 - Padconfig register is locked from further writes
  [30] PADCONFIG76_WKUP_EVT_PROXY ro — Wakeup event status 0 - No wake event on pin 1 - Wake event occurred on pin
  [29] PADCONFIG76_WKUP_EN_PROXY rw — Wakeup enable 0 - Wakeup operation disabled 1 - Wakeup operation enabled
  [28] PADCONFIG76_DS_PULLTYPE_SEL_PROXY rw — Deep Sleep pull-up/down selection 0 - Offmode pulldown selected 1 - Offmode pullup selected
  [27] PADCONFIG76_DS_PULLUD_EN_PROXY rw — Deep Sleep pull-up/down enable (active low) 0 - Pullup / pulldown is enabled 1 - Pullup / pulldown is disabled
  [26] PADCONFIG76_DSOUT_VAL_PROXY rw — Deep Sleep output value 0 - Output value is 0 1 - Output value is 1
  [25] PADCONFIG76_DSOUT_DIS_PROXY rw — Deep Sleep output enable 0 - Output enabled 1 - Output disabled
  [24] PADCONFIG76_DS_EN_PROXY rw — Deep Sleep override control 0 - IO keeps its previous state when Deep Sleep is active 1 - IO state is forced to OFF mode value when Deep Sleep is active
  [23] PADCONFIG76_ISO_BYP_PROXY rw — Isolation Bypass 0 - IO isolation is preserved 1 - IO isolation is bypassed
  [22] PADCONFIG76_ISO_OVR_PROXY rw — Isolation Override 0 - IO isolation is preserved 1 - IO isolation is overridden
  [21] PADCONFIG76_TX_DIS_PROXY rw — Driver Disable 0 - Driver is enabled 1 - Driver is disabled
  [20:19] PADCONFIG76_DRV_STR_PROXY rw — Drive Strength Control . Selects the drive strength value for LVCMOS pins. (Does not apply to other pin types)
  [18] PADCONFIG76_RXACTIVE_PROXY rw — Input enable for the Pad 0 - Receiver disabled 1 - Receiver enabled
  [17] PADCONFIG76_PULLTYPESEL_PROXY rw — Pad Pullup / Pulldown type selection 0 - Pulldown selected 1 - Pullup selected
  [16] PADCONFIG76_PULLUDEN_PROXY rw — Pad Pullup / Pulldown enable. This is an active low signal. 0 - Pullup / Pulldown enabled 1 - Pullup / Pulldown disabled
  [15] PADCONFIG76_FORCE_DS_EN_PROXY rw — Enable pad Deep Sleep controls by overriding SMS gating 0 - Deep Sleep pad controls are gated by the SMS 1 - Activate Deep Sleep pad controls (override SMS gating logic)
  [14] PADCONFIG76_ST_EN_PROXY rw — Receiver Schmitt Trigger enable 0 - Schmitt trigger input disabled 1 - Schmitt trigger input enabled
  [13:11] PADCONFIG76_DEBOUNCE_SEL_PROXY rw — Selects the debounce period for the pad.
  [8] PADCONFIG76_WK_LVL_POL_PROXY rw — Level Sensitive Wakeup Polarity This bit is not relevant unless wk_lvl_en is set to 1'b1. 0 - Low. A low (0) value on the pin causes a wakeup 1 - High. A high (1) value on the pin causes a wakeup
  [7] PADCONFIG76_WK_LVL_EN_PROXY rw — Level Sensitive Wakeup Enable 0 - Disabled. Wakeup is triggered by change of the pin input value 1 - Enabled. Wakeup is triggered when the pin matches the value specified by wk_lvl_pol. The chosen polarity must be maintained. (e.g. until wakeup completion is confirmed)
  [5:4] PADCONFIG76_VGPIO_SEL_PROXY rw — Virtual WKUP_GPIO instance select. These bits select which instance of GPIO is used for this I/O pad. This allows protection between two different Processor virtual worlds. These bits have no effect if GPIO mode (muxmode=7) is not selected for the PAD. Field values (others are reserved): 2'b00 - Implement GPIO in GPIO_WKUP_0 instance 2'b01 - Implement GPIO in GPIO_WKUP_1 instance
  [3:0] PADCONFIG76_MUXMODE_PROXY rw — Pad functional signal mux selection Field values (others are reserved): 0000b - Mux Mode 0 0001b - Mux Mode 1 0010b - Mux Mode 2 0011b - Mux Mode 3 0100b - Mux Mode 4 0101b - Mux Mode 5 0110b - Mux Mode 6 0111b - Mux Mode 7 1111b - Mux Mode 15
{0x1E000+4i} CFG0_PADCONFIG{i}_PROXY (i=77..84)
  [31] PADCONFIG{i}_LOCK_PROXY — Lock 0 - Padconfig register is unlocked 1 - Padconfig register is locked from further writes
  [13:11] PADCONFIG{i}_DEBOUNCE_SEL_PROXY — Selects the debounce period for the pad.
  [5:4] PADCONFIG{i}_VGPIO_SEL_PROXY — Virtual WKUP_GPIO instance select. These bits select which instance of GPIO is used for this pin. This allows protection between two different Processor virtual worlds. These bits have no effect if GPI mode is not selected for ADC0 (MCU_ADC0_CTRL_gpi_mode_en=1) Field values (others are reserved): 2'b00 - Implement GPIO in GPIO_WKUP_0 instance 2'b01 - Implement GPIO in GPIO_WKUP_1 instance
{0x1E000+4i} CFG0_PADCONFIG{i}_PROXY (i=85..92)
  [31] PADCONFIG{i}_LOCK_PROXY — Lock 0 - Padconfig register is unlocked 1 - Padconfig register is locked from further writes
  [13:11] PADCONFIG{i}_DEBOUNCE_SEL_PROXY — Selects the debounce period for the pad.
  [5:4] PADCONFIG{i}_VGPIO_SEL_PROXY — Virtual WKUP_GPIO instance select. These bits select which instance of GPIO is used for this pin. This allows protection between two different Processor virtual worlds. These bits have no effect if GPI mode is not selected for ADC1 (MCU_ADC1_CTRL_gpi_mode_en=1) Field values (others are reserved): 2'b00 - Implement GPIO in GPIO_WKUP_0 instance 2'b01 - Implement GPIO in GPIO_WKUP_1 instance
0x1E174 CFG0_PADCONFIG93_PROXY access per field reset 0x10264000
  [31] PADCONFIG93_LOCK_PROXY rw — Lock 0 - Padconfig register is unlocked 1 - Padconfig register is locked from further writes
  [30] PADCONFIG93_WKUP_EVT_PROXY ro — Wakeup event status 0 - No wake event on pin 1 - Wake event occurred on pin
  [29] PADCONFIG93_WKUP_EN_PROXY rw — Wakeup enable 0 - Wakeup operation disabled 1 - Wakeup operation enabled
  [28] PADCONFIG93_DS_PULLTYPE_SEL_PROXY rw — Deep Sleep pull-up/down selection 0 - Offmode pulldown selected 1 - Offmode pullup selected
  [27] PADCONFIG93_DS_PULLUD_EN_PROXY rw — Deep Sleep pull-up/down enable (active low) 0 - Pullup / pulldown is enabled 1 - Pullup / pulldown is disabled
  [26] PADCONFIG93_DSOUT_VAL_PROXY rw — Deep Sleep output value 0 - Output value is 0 1 - Output value is 1
  [25] PADCONFIG93_DSOUT_DIS_PROXY rw — Deep Sleep output enable 0 - Output enabled 1 - Output disabled
  [24] PADCONFIG93_DS_EN_PROXY rw — Deep Sleep override control 0 - IO keeps its previous state when Deep Sleep is active 1 - IO state is forced to OFF mode value when Deep Sleep is active
  [23] PADCONFIG93_ISO_BYP_PROXY rw — Isolation Bypass 0 - IO isolation is preserved 1 - IO isolation is bypassed
  [22] PADCONFIG93_ISO_OVR_PROXY rw — Isolation Override 0 - IO isolation is preserved 1 - IO isolation is overridden
  [21] PADCONFIG93_TX_DIS_PROXY rw — Driver Disable 0 - Driver is enabled 1 - Driver is disabled
  [20:19] PADCONFIG93_DRV_STR_PROXY rw — Drive Strength Control . Selects the drive strength value for LVCMOS pins. (Does not apply to other pin types)
  [18] PADCONFIG93_RXACTIVE_PROXY rw — Input enable for the Pad 0 - Receiver disabled 1 - Receiver enabled
  [17] PADCONFIG93_PULLTYPESEL_PROXY rw — Pad Pullup / Pulldown type selection 0 - Pulldown selected 1 - Pullup selected
  [16] PADCONFIG93_PULLUDEN_PROXY rw — Pad Pullup / Pulldown enable. This is an active low signal. 0 - Pullup / Pulldown enabled 1 - Pullup / Pulldown disabled
  [15] PADCONFIG93_FORCE_DS_EN_PROXY rw — Enable pad Deep Sleep controls by overriding SMS gating 0 - Deep Sleep pad controls are gated by the SMS 1 - Activate Deep Sleep pad controls (override SMS gating logic)
  [14] PADCONFIG93_ST_EN_PROXY rw — Receiver Schmitt Trigger enable 0 - Schmitt trigger input disabled 1 - Schmitt trigger input enabled
  [13:11] PADCONFIG93_DEBOUNCE_SEL_PROXY rw — Selects the debounce period for the pad.
  [8] PADCONFIG93_WK_LVL_POL_PROXY rw — Level Sensitive Wakeup Polarity This bit is not relevant unless wk_lvl_en is set to 1'b1. 0 - Low. A low (0) value on the pin causes a wakeup 1 - High. A high (1) value on the pin causes a wakeup
  [7] PADCONFIG93_WK_LVL_EN_PROXY rw — Level Sensitive Wakeup Enable 0 - Disabled. Wakeup is triggered by change of the pin input value 1 - Enabled. Wakeup is triggered when the pin matches the value specified by wk_lvl_pol. The chosen polarity must be maintained. (e.g. until wakeup completion is confirmed)
  [5:4] PADCONFIG93_VGPIO_SEL_PROXY rw — Virtual WKUP_GPIO instance select. These bits select which instance of GPIO is used for this I/O pad. This allows protection between two different Processor virtual worlds. These bits have no effect if GPIO mode (muxmode=7) is not selected for the PAD. Field values (others are reserved): 2'b00 - Implement GPIO in GPIO_WKUP_0 instance 2'b01 - Implement GPIO in GPIO_WKUP_1 instance
  [3:0] PADCONFIG93_MUXMODE_PROXY rw — Pad functional signal mux selection Field values (others are reserved): 0000b - Mux Mode 0 0001b - Mux Mode 1 0010b - Mux Mode 2 0011b - Mux Mode 3 0100b - Mux Mode 4 0101b - Mux Mode 5 0110b - Mux Mode 6 0111b - Mux Mode 7 1111b - Mux Mode 15
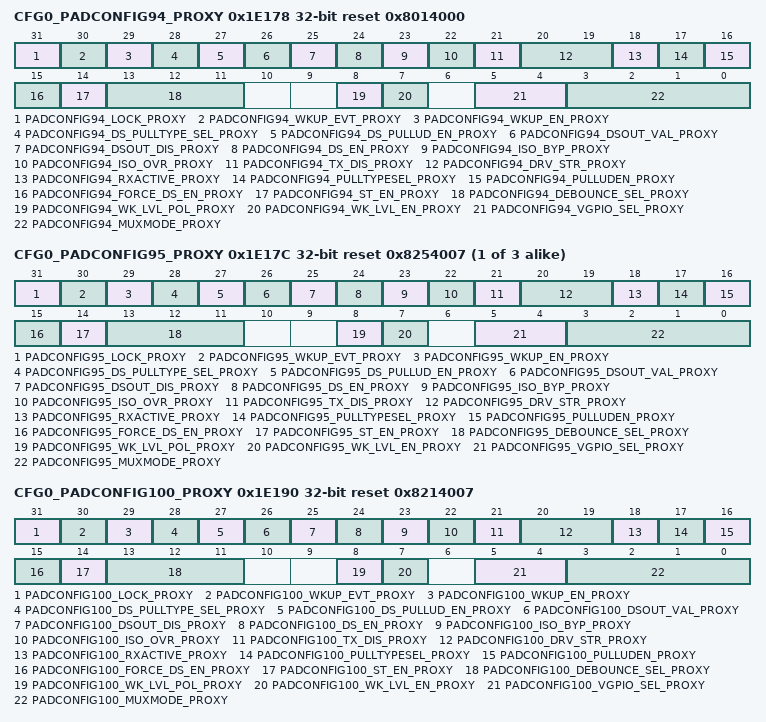
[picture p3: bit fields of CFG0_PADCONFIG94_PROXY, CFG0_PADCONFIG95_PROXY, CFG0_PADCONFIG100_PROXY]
0x1E178 CFG0_PADCONFIG94_PROXY access per field reset 0x8014000
  [31] PADCONFIG94_LOCK_PROXY rw — Lock 0 - Padconfig register is unlocked 1 - Padconfig register is locked from further writes
  [30] PADCONFIG94_WKUP_EVT_PROXY ro — Wakeup event status 0 - No wake event on pin 1 - Wake event occurred on pin
  [29] PADCONFIG94_WKUP_EN_PROXY rw — Wakeup enable 0 - Wakeup operation disabled 1 - Wakeup operation enabled
  [28] PADCONFIG94_DS_PULLTYPE_SEL_PROXY rw — Deep Sleep pull-up/down selection 0 - Offmode pulldown selected 1 - Offmode pullup selected
  [27] PADCONFIG94_DS_PULLUD_EN_PROXY rw — Deep Sleep pull-up/down enable (active low) 0 - Pullup / pulldown is enabled 1 - Pullup / pulldown is disabled
  [26] PADCONFIG94_DSOUT_VAL_PROXY rw — Deep Sleep output value 0 - Output value is 0 1 - Output value is 1
  [25] PADCONFIG94_DSOUT_DIS_PROXY rw — Deep Sleep output enable 0 - Output enabled 1 - Output disabled
  [24] PADCONFIG94_DS_EN_PROXY rw — Deep Sleep override control 0 - IO keeps its previous state when Deep Sleep is active 1 - IO state is forced to OFF mode value when Deep Sleep is active
  [23] PADCONFIG94_ISO_BYP_PROXY rw — Isolation Bypass 0 - IO isolation is preserved 1 - IO isolation is bypassed
  [22] PADCONFIG94_ISO_OVR_PROXY rw — Isolation Override 0 - IO isolation is preserved 1 - IO isolation is overridden
  [21] PADCONFIG94_TX_DIS_PROXY rw — Driver Disable 0 - Driver is enabled 1 - Driver is disabled
  [20:19] PADCONFIG94_DRV_STR_PROXY rw — Drive Strength Control . Selects the drive strength value for LVCMOS pins. (Does not apply to other pin types)
  [18] PADCONFIG94_RXACTIVE_PROXY rw — Input enable for the Pad 0 - Receiver disabled 1 - Receiver enabled
  [17] PADCONFIG94_PULLTYPESEL_PROXY rw — Pad Pullup / Pulldown type selection 0 - Pulldown selected 1 - Pullup selected
  [16] PADCONFIG94_PULLUDEN_PROXY rw — Pad Pullup / Pulldown enable. This is an active low signal. 0 - Pullup / Pulldown enabled 1 - Pullup / Pulldown disabled
  [15] PADCONFIG94_FORCE_DS_EN_PROXY rw — Enable pad Deep Sleep controls by overriding SMS gating 0 - Deep Sleep pad controls are gated by the SMS 1 - Activate Deep Sleep pad controls (override SMS gating logic)
  [14] PADCONFIG94_ST_EN_PROXY rw — Receiver Schmitt Trigger enable 0 - Schmitt trigger input disabled 1 - Schmitt trigger input enabled
  [13:11] PADCONFIG94_DEBOUNCE_SEL_PROXY rw — Selects the debounce period for the pad.
  [8] PADCONFIG94_WK_LVL_POL_PROXY rw — Level Sensitive Wakeup Polarity This bit is not relevant unless wk_lvl_en is set to 1'b1. 0 - Low. A low (0) value on the pin causes a wakeup 1 - High. A high (1) value on the pin causes a wakeup
  [7] PADCONFIG94_WK_LVL_EN_PROXY rw — Level Sensitive Wakeup Enable 0 - Disabled. Wakeup is triggered by change of the pin input value 1 - Enabled. Wakeup is triggered when the pin matches the value specified by wk_lvl_pol. The chosen polarity must be maintained. (e.g. until wakeup completion is confirmed)
  [5:4] PADCONFIG94_VGPIO_SEL_PROXY rw — Virtual WKUP_GPIO instance select. These bits select which instance of GPIO is used for this I/O pad. This allows protection between two different Processor virtual worlds. These bits have no effect if GPIO mode (muxmode=7) is not selected for the PAD. Field values (others are reserved): 2'b00 - Implement GPIO in GPIO_WKUP_0 instance 2'b01 - Implement GPIO in GPIO_WKUP_1 instance
  [3:0] PADCONFIG94_MUXMODE_PROXY rw — Pad functional signal mux selection Field values (others are reserved): 0000b - Mux Mode 0 0001b - Mux Mode 1 0010b - Mux Mode 2 0011b - Mux Mode 3 0100b - Mux Mode 4 0101b - Mux Mode 5 0110b - Mux Mode 6 0111b - Mux Mode 7 1111b - Mux Mode 15
{0x1E000+4i} CFG0_PADCONFIG{i}_PROXY access per field reset 0x8254007 (i=95..97)
  [31] PADCONFIG{i}_LOCK_PROXY rw — Lock 0 - Padconfig register is unlocked 1 - Padconfig register is locked from further writes
  [30] PADCONFIG{i}_WKUP_EVT_PROXY ro — Wakeup event status 0 - No wake event on pin 1 - Wake event occurred on pin
  [29] PADCONFIG{i}_WKUP_EN_PROXY rw — Wakeup enable 0 - Wakeup operation disabled 1 - Wakeup operation enabled
  [28] PADCONFIG{i}_DS_PULLTYPE_SEL_PROXY rw — Deep Sleep pull-up/down selection 0 - Offmode pulldown selected 1 - Offmode pullup selected
  [27] PADCONFIG{i}_DS_PULLUD_EN_PROXY rw — Deep Sleep pull-up/down enable (active low) 0 - Pullup / pulldown is enabled 1 - Pullup / pulldown is disabled
  [26] PADCONFIG{i}_DSOUT_VAL_PROXY rw — Deep Sleep output value 0 - Output value is 0 1 - Output value is 1
  [25] PADCONFIG{i}_DSOUT_DIS_PROXY rw — Deep Sleep output enable 0 - Output enabled 1 - Output disabled
  [24] PADCONFIG{i}_DS_EN_PROXY rw — Deep Sleep override control 0 - IO keeps its previous state when Deep Sleep is active 1 - IO state is forced to OFF mode value when Deep Sleep is active
  [23] PADCONFIG{i}_ISO_BYP_PROXY rw — Isolation Bypass 0 - IO isolation is preserved 1 - IO isolation is bypassed
  [22] PADCONFIG{i}_ISO_OVR_PROXY rw — Isolation Override 0 - IO isolation is preserved 1 - IO isolation is overridden
  [21] PADCONFIG{i}_TX_DIS_PROXY rw — Driver Disable 0 - Driver is enabled 1 - Driver is disabled
  [20:19] PADCONFIG{i}_DRV_STR_PROXY rw — Drive Strength Control . Selects the drive strength value for LVCMOS pins. (Does not apply to other pin types)
  [18] PADCONFIG{i}_RXACTIVE_PROXY rw — Input enable for the Pad 0 - Receiver disabled 1 - Receiver enabled
  [17] PADCONFIG{i}_PULLTYPESEL_PROXY rw — Pad Pullup / Pulldown type selection 0 - Pulldown selected 1 - Pullup selected
  [16] PADCONFIG{i}_PULLUDEN_PROXY rw — Pad Pullup / Pulldown enable. This is an active low signal. 0 - Pullup / Pulldown enabled 1 - Pullup / Pulldown disabled
  [15] PADCONFIG{i}_FORCE_DS_EN_PROXY rw — Enable pad Deep Sleep controls by overriding SMS gating 0 - Deep Sleep pad controls are gated by the SMS 1 - Activate Deep Sleep pad controls (override SMS gating logic)
  [14] PADCONFIG{i}_ST_EN_PROXY rw — Receiver Schmitt Trigger enable 0 - Schmitt trigger input disabled 1 - Schmitt trigger input enabled
  [13:11] PADCONFIG{i}_DEBOUNCE_SEL_PROXY rw — Selects the debounce period for the pad.
  [8] PADCONFIG{i}_WK_LVL_POL_PROXY rw — Level Sensitive Wakeup Polarity This bit is not relevant unless wk_lvl_en is set to 1'b1. 0 - Low. A low (0) value on the pin causes a wakeup 1 - High. A high (1) value on the pin causes a wakeup
  [7] PADCONFIG{i}_WK_LVL_EN_PROXY rw — Level Sensitive Wakeup Enable 0 - Disabled. Wakeup is triggered by change of the pin input value 1 - Enabled. Wakeup is triggered when the pin matches the value specified by wk_lvl_pol. The chosen polarity must be maintained. (e.g. until wakeup completion is confirmed)
  [5:4] PADCONFIG{i}_VGPIO_SEL_PROXY rw — Virtual WKUP_GPIO instance select. These bits select which instance of GPIO is used for this I/O pad. This allows protection between two different Processor virtual worlds. These bits have no effect if GPIO mode (muxmode=7) is not selected for the PAD. Field values (others are reserved): 2'b00 - Implement GPIO in GPIO_WKUP_0 instance 2'b01 - Implement GPIO in GPIO_WKUP_1 instance
  [3:0] PADCONFIG{i}_MUXMODE_PROXY rw — Pad functional signal mux selection Field values (others are reserved): 0000b - Mux Mode 0 0001b - Mux Mode 1 0010b - Mux Mode 2 0011b - Mux Mode 3 0100b - Mux Mode 4 0101b - Mux Mode 5 0110b - Mux Mode 6 0111b - Mux Mode 7 1111b - Mux Mode 15
0x1E190 CFG0_PADCONFIG100_PROXY access per field reset 0x8214007
  [31] PADCONFIG100_LOCK_PROXY rw — Lock 0 - Padconfig register is unlocked 1 - Padconfig register is locked from further writes
  [30] PADCONFIG100_WKUP_EVT_PROXY ro — Wakeup event status 0 - No wake event on pin 1 - Wake event occurred on pin
  [29] PADCONFIG100_WKUP_EN_PROXY rw — Wakeup enable 0 - Wakeup operation disabled 1 - Wakeup operation enabled
  [28] PADCONFIG100_DS_PULLTYPE_SEL_PROXY rw — Deep Sleep pull-up/down selection 0 - Offmode pulldown selected 1 - Offmode pullup selected
  [27] PADCONFIG100_DS_PULLUD_EN_PROXY rw — Deep Sleep pull-up/down enable (active low) 0 - Pullup / pulldown is enabled 1 - Pullup / pulldown is disabled
  [26] PADCONFIG100_DSOUT_VAL_PROXY rw — Deep Sleep output value 0 - Output value is 0 1 - Output value is 1
  [25] PADCONFIG100_DSOUT_DIS_PROXY rw — Deep Sleep output enable 0 - Output enabled 1 - Output disabled
  [24] PADCONFIG100_DS_EN_PROXY rw — Deep Sleep override control 0 - IO keeps its previous state when Deep Sleep is active 1 - IO state is forced to OFF mode value when Deep Sleep is active
  [23] PADCONFIG100_ISO_BYP_PROXY rw — Isolation Bypass 0 - IO isolation is preserved 1 - IO isolation is bypassed
  [22] PADCONFIG100_ISO_OVR_PROXY rw — Isolation Override 0 - IO isolation is preserved 1 - IO isolation is overridden
  [21] PADCONFIG100_TX_DIS_PROXY rw — Driver Disable 0 - Driver is enabled 1 - Driver is disabled
  [20:19] PADCONFIG100_DRV_STR_PROXY rw — Drive Strength Control . Selects the drive strength value for LVCMOS pins. (Does not apply to other pin types)
  [18] PADCONFIG100_RXACTIVE_PROXY rw — Input enable for the Pad 0 - Receiver disabled 1 - Receiver enabled
  [17] PADCONFIG100_PULLTYPESEL_PROXY rw — Pad Pullup / Pulldown type selection 0 - Pulldown selected 1 - Pullup selected
  [16] PADCONFIG100_PULLUDEN_PROXY rw — Pad Pullup / Pulldown enable. This is an active low signal. 0 - Pullup / Pulldown enabled 1 - Pullup / Pulldown disabled
  [15] PADCONFIG100_FORCE_DS_EN_PROXY rw — Enable pad Deep Sleep controls by overriding SMS gating 0 - Deep Sleep pad controls are gated by the SMS 1 - Activate Deep Sleep pad controls (override SMS gating logic)
  [14] PADCONFIG100_ST_EN_PROXY rw — Receiver Schmitt Trigger enable 0 - Schmitt trigger input disabled 1 - Schmitt trigger input enabled
  [13:11] PADCONFIG100_DEBOUNCE_SEL_PROXY rw — Selects the debounce period for the pad.
  [8] PADCONFIG100_WK_LVL_POL_PROXY rw — Level Sensitive Wakeup Polarity This bit is not relevant unless wk_lvl_en is set to 1'b1. 0 - Low. A low (0) value on the pin causes a wakeup 1 - High. A high (1) value on the pin causes a wakeup
  [7] PADCONFIG100_WK_LVL_EN_PROXY rw — Level Sensitive Wakeup Enable 0 - Disabled. Wakeup is triggered by change of the pin input value 1 - Enabled. Wakeup is triggered when the pin matches the value specified by wk_lvl_pol. The chosen polarity must be maintained. (e.g. until wakeup completion is confirmed)
  [5:4] PADCONFIG100_VGPIO_SEL_PROXY rw — Virtual WKUP_GPIO instance select. These bits select which instance of GPIO is used for this I/O pad. This allows protection between two different Processor virtual worlds. These bits have no effect if GPIO mode (muxmode=7) is not selected for the PAD. Field values (others are reserved): 2'b00 - Implement GPIO in GPIO_WKUP_0 instance 2'b01 - Implement GPIO in GPIO_WKUP_1 instance
  [3:0] PADCONFIG100_MUXMODE_PROXY rw — Pad functional signal mux selection Field values (others are reserved): 0000b - Mux Mode 0 0001b - Mux Mode 1 0010b - Mux Mode 2 0011b - Mux Mode 3 0100b - Mux Mode 4 0101b - Mux Mode 5 0110b - Mux Mode 6 0111b - Mux Mode 7 1111b - Mux Mode 15
{0x1F100+4i} CFG0_CLAIMREG_P7_R{i} (i=0..3)
  [31:0] CLAIMREG_P7_R{i} — Claim bits for Partition 7
